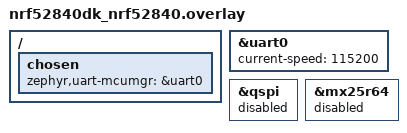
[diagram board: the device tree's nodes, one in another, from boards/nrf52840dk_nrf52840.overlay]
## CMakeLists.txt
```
cmake_minimum_required(VERSION 3.20.0)

find_package(Zephyr REQUIRED HINTS $ENV{ZEPHYR_BASE})
project(tx_node)

target_sources(app PRIVATE
	src/main.c
	src/ble_link.c
	src/packet_framer.c
	src/tsync.c
	src/dfu_auth.c
	src/wdt_monitor.c
	src/imu_uart_driver.c
	src/uwb_driver.c
)

target_include_directories(app PRIVATE
	${CMAKE_CURRENT_SOURCE_DIR}/include
	${CMAKE_CURRENT_SOURCE_DIR}/../shared/include
)
```

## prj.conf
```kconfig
CONFIG_BT=y
CONFIG_BT_PERIPHERAL=y
CONFIG_BT_CENTRAL=n
CONFIG_BT_DEVICE_NAME="BSGR_TX01"
CONFIG_BT_DEVICE_APPEARANCE=0
CONFIG_BT_SMP=y
CONFIG_BT_PRIVACY=y
CONFIG_BT_BONDABLE=y
CONFIG_BT_SETTINGS=y
CONFIG_BT_GATT_DYNAMIC_DB=y
CONFIG_BT_GATT_SERVICE_CHANGED=y
CONFIG_BT_MAX_CONN=1
CONFIG_BT_NUS=y
CONFIG_BT_NUS_CLIENT=n
CONFIG_BT_CTLR_PHY_2M=y
CONFIG_BT_USER_PHY_UPDATE=y
CONFIG_BT_CTLR_DATA_LENGTH_MAX=251
CONFIG_BT_L2CAP_TX_MTU=247
CONFIG_BT_BUF_ACL_RX_SIZE=251
CONFIG_BT_BUF_ACL_TX_SIZE=251
CONFIG_BT_BUF_ACL_RX_COUNT=8
CONFIG_BT_BUF_ACL_TX_COUNT=12
CONFIG_BT_L2CAP_TX_BUF_COUNT=12
CONFIG_BT_BUF_CMD_TX_COUNT=6
CONFIG_BT_BUF_EVT_RX_SIZE=255
CONFIG_BT_BUF_EVT_RX_COUNT=8

CONFIG_BOOTLOADER_MCUBOOT=y
CONFIG_MCUBOOT_BOOTUTIL_LIB=y
CONFIG_MCUBOOT_IMGTOOL_SIGN_VERSION="0.1.0+4"
CONFIG_FLASH=y
CONFIG_FLASH_PAGE_LAYOUT=y
CONFIG_FLASH_MAP=y
CONFIG_STREAM_FLASH=y
CONFIG_IMG_MANAGER=y
CONFIG_MCUMGR=y
CONFIG_MCUMGR_GRP_IMG=y
CONFIG_MCUMGR_GRP_OS=y
CONFIG_MCUMGR_GRP_OS_BOOTLOADER_INFO=y
CONFIG_MCUMGR_GRP_OS_MCUMGR_PARAMS=y
CONFIG_MCUMGR_TRANSPORT_BT=y
CONFIG_MCUMGR_TRANSPORT_BT_PERM_RW_AUTHEN=y
CONFIG_MCUMGR_TRANSPORT_BT_CONN_PARAM_CONTROL=y
CONFIG_MCUMGR_TRANSPORT_BT_REASSEMBLY=y
CONFIG_MCUMGR_TRANSPORT_NETBUF_SIZE=768
CONFIG_ZCBOR=y
CONFIG_CRC=y
CONFIG_NET_BUF=y

CONFIG_SETTINGS=y
CONFIG_REBOOT=y
CONFIG_WATCHDOG=y
CONFIG_GPIO=y
CONFIG_SERIAL=y
CONFIG_UART_INTERRUPT_DRIVEN=y
CONFIG_RING_BUFFER=y
CONFIG_ASSERT=y

CONFIG_LOG=y
CONFIG_LOG_DEFAULT_LEVEL=3
CONFIG_LOG_MODE_DEFERRED=y
CONFIG_LOG_BACKEND_RTT=y
CONFIG_LOG_BACKEND_UART=n
CONFIG_USE_SEGGER_RTT=y
CONFIG_RTT_CONSOLE=y
CONFIG_CONSOLE=y
CONFIG_UART_CONSOLE=n
CONFIG_PRINTK=y

CONFIG_MAIN_STACK_SIZE=4096
CONFIG_SYSTEM_WORKQUEUE_STACK_SIZE=4096
CONFIG_ISR_STACK_SIZE=2048
CONFIG_HEAP_MEM_POOL_SIZE=8192
```

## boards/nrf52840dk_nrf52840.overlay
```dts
/ {
	chosen {
		zephyr,uart-mcumgr = &uart0;
	};
};

&uart0 {
	status = "okay";
	current-speed = <115200>;
};

&qspi {
	status = "disabled";
};

&mx25r64 {
	status = "disabled";
};
```

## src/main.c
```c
#include <zephyr/kernel.h>
#include <zephyr/logging/log.h>

#include "ble_link.h"
#include "dfu_auth.h"
#include "imu_uart_driver.h"
#include "packet_framer.h"
#include "tsync.h"
#include "tx_node.h"
#include "uwb_driver.h"
#include "wdt_monitor.h"

LOG_MODULE_REGISTER(tx_main, LOG_LEVEL_INF);

static struct k_work_delayable tx_service_work;
static uint16_t tx_seq;
static int64_t last_status_ms;

static void tx_submit_boot_status(enum bsgr_status_code code, uint16_t detail, uint32_t value)
{
	struct bsgr_status_payload status = {
		.status_code = code,
		.origin = BSGR_ORIGIN_SYSTEM,
		.detail = detail,
		.value = value,
	};
	struct bsgr_tx_frame frame;

	if (packet_framer_build_status(BSGR_TX_DEVICE_ID, tx_seq++, &status, &frame) == 0) {
		(void)ble_link_submit_frame(&frame);
	}
}

static void tx_drain_imu_samples(void)
{
	struct bsgr_imu_sample *sample;

	while ((sample = imu_uart_driver_pop_sample()) != NULL) {
		struct bsgr_imu_batch_meta meta = {
			.stream_flags = BSGR_STREAM_FLAG_IMU,
			.sample_count = 1U,
			.parser_flags = sample->parser_flags,
			.reserved = 0U,
			.host_capture_ticks = sample->host_capture_ticks,
			.sample_stride = sample->raw_len,
			.raw_bytes = sample->raw_len,
		};
		struct bsgr_tx_frame frame;

		if (packet_framer_build_imu(BSGR_TX_DEVICE_ID, tx_seq++, &meta,
					    sample->raw, sample->raw_len, &frame) == 0) {
			(void)ble_link_submit_frame(&frame);
		}
		k_free(sample);
	}
}

static void tx_drain_uwb_records(void)
{
	struct bsgr_uwb_record *record;

	while ((record = uwb_driver_pop_record()) != NULL) {
		struct bsgr_uwb_report_meta meta = {
			.stream_flags = BSGR_STREAM_FLAG_UWB,
			.record_count = 1U,
			.parser_flags = record->parser_flags,
			.reserved = 0U,
			.host_capture_ticks = record->host_capture_ticks,
			.record_stride = record->raw_len,
			.raw_bytes = record->raw_len,
		};
		struct bsgr_tx_frame frame;

		if (packet_framer_build_uwb(BSGR_TX_DEVICE_ID, tx_seq++, &meta,
					    record->raw, record->raw_len, &frame) == 0) {
			(void)ble_link_submit_frame(&frame);
		}
		k_free(record);
	}
}

static void tx_service_work_handler(struct k_work *work)
{
	int64_t now_ms = k_uptime_get();

	ARG_UNUSED(work);

	imu_uart_driver_process();
	uwb_driver_process();
	tx_drain_imu_samples();
	tx_drain_uwb_records();
	ble_link_schedule_drain();
	wdt_monitor_feed();

	if ((now_ms - last_status_ms) >= BSGR_TX_STATUS_PERIOD_MS) {
		tx_submit_boot_status(BSGR_STATUS_STREAM_IDLE, 0U,
				     (uint32_t)ble_link_is_connected());
		last_status_ms = now_ms;
	}

	(void)k_work_reschedule(&tx_service_work, K_MSEC(BSGR_TX_SERVICE_PERIOD_MS));
}

int tx_main_init(void)
{
	int err;

	LOG_INF("BSGR TX framework bring-up");

	dfu_auth_init();
	tsync_init();

	err = wdt_monitor_init();
	if (err != 0) {
		return err;
	}

	err = imu_uart_driver_init();
	if (err != 0) {
		LOG_WRN("IMU driver init degraded: %d", err);
	}

	err = uwb_driver_init();
	if (err != 0) {
		LOG_WRN("UWB driver init degraded: %d", err);
	}

	(void)imu_uart_driver_start();
	(void)uwb_driver_start();

	err = ble_link_init(BSGR_TX_DEVICE_ID);
	if (err != 0) {
		return err;
	}

	k_work_init_delayable(&tx_service_work, tx_service_work_handler);
	tx_seq = 0U;
	last_status_ms = 0;
	tx_submit_boot_status(BSGR_STATUS_BOOT, 0U, tsync_get_session_id());
	(void)k_work_reschedule(&tx_service_work, K_NO_WAIT);

	return 0;
}

int main(void)
{
	int err = tx_main_init();

	if (err != 0) {
		LOG_ERR("tx_main_init failed: %d", err);
		return err;
	}

	while (1) {
		k_sleep(K_SECONDS(1));
	}

	return 0;
}
```

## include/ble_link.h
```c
#ifndef BSGR_TX_BLE_LINK_H_
#define BSGR_TX_BLE_LINK_H_

#include <stdbool.h>
#include <stddef.h>
#include <stdint.h>

#include "packet_framer.h"

int ble_link_init(uint16_t device_id);
int ble_link_submit_frame(const struct bsgr_tx_frame *frame);
void ble_link_schedule_drain(void);
bool ble_link_is_connected(void);

#endif /* BSGR_TX_BLE_LINK_H_ */
```

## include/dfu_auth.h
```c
#ifndef BSGR_TX_DFU_AUTH_H_
#define BSGR_TX_DFU_AUTH_H_

#include <stdbool.h>
#include <stdint.h>

#include "bsgr_protocol.h"

struct bsgr_dfu_auth_state {
	bool prepared;
	bool authorized;
	bool active;
	uint16_t session_id;
	uint16_t last_request_id;
	enum bsgr_cmd_result last_result;
};

void dfu_auth_init(void);
void dfu_auth_prepare(uint16_t request_id);
void dfu_auth_set_authorized(bool authorized, uint16_t request_id);
void dfu_auth_begin(uint16_t session_id);
void dfu_auth_end(void);
bool dfu_auth_is_permitted(void);
const struct bsgr_dfu_auth_state *dfu_auth_state_get(void);

#endif /* BSGR_TX_DFU_AUTH_H_ */
```

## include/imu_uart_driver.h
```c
#ifndef BSGR_TX_IMU_UART_DRIVER_H_
#define BSGR_TX_IMU_UART_DRIVER_H_

#include <stdbool.h>
#include <stddef.h>
#include <stdint.h>

#include "bsgr_protocol.h"

struct bsgr_imu_sample {
	void *fifo_reserved;
	uint32_t host_capture_ticks;
	uint16_t parser_flags;
	uint16_t raw_len;
	uint8_t raw[BSGR_IMU_MAX_RAW_FRAME_LEN];
};

int imu_uart_driver_init(void);
int imu_uart_driver_start(void);
void imu_uart_driver_stop(void);
bool imu_uart_driver_is_bound(void);
void imu_uart_driver_process(void);
int imu_uart_driver_ingest_bytes(const uint8_t *data, size_t len, uint32_t capture_ticks);
struct bsgr_imu_sample *imu_uart_driver_pop_sample(void);

#endif /* BSGR_TX_IMU_UART_DRIVER_H_ */
```

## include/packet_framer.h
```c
#ifndef BSGR_TX_PACKET_FRAMER_H_
#define BSGR_TX_PACKET_FRAMER_H_

#include <stddef.h>
#include <stdint.h>

#include "bsgr_protocol.h"

struct bsgr_tx_frame {
	size_t len;
	uint8_t data[BSGR_MAX_FRAME_LEN];
};

struct bsgr_imu_sample;
struct bsgr_uwb_record;

int packet_framer_build_status(uint16_t device_id,
			       uint16_t seq,
			       const struct bsgr_status_payload *payload,
			       struct bsgr_tx_frame *frame);
int packet_framer_build_cmd_ack(uint16_t device_id,
				uint16_t seq,
				const struct bsgr_cmd_ack_payload *payload,
				struct bsgr_tx_frame *frame);
int packet_framer_build_tsync(uint16_t device_id,
			      uint16_t seq,
			      const struct bsgr_tsync_payload *payload,
			      struct bsgr_tx_frame *frame);
int packet_framer_build_imu(uint16_t device_id,
			    uint16_t seq,
			    const struct bsgr_imu_batch_meta *meta,
			    const uint8_t *raw_payload,
			    size_t raw_len,
			    struct bsgr_tx_frame *frame);
int packet_framer_build_uwb(uint16_t device_id,
			    uint16_t seq,
			    const struct bsgr_uwb_report_meta *meta,
			    const uint8_t *raw_payload,
			    size_t raw_len,
			    struct bsgr_tx_frame *frame);

#endif /* BSGR_TX_PACKET_FRAMER_H_ */
```

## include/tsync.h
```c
#ifndef BSGR_TX_TSYNC_H_
#define BSGR_TX_TSYNC_H_

#include <stdint.h>

#include "bsgr_protocol.h"

struct bsgr_tsync_state {
	int32_t host_offset_ms;
	uint16_t session_id;
	uint16_t last_request_id;
};

void tsync_init(void);
void tsync_set_host_offset_ms(int32_t offset_ms);
int32_t tsync_get_host_offset_ms(void);
uint16_t tsync_next_request_id(void);
uint16_t tsync_get_session_id(void);
void tsync_advance_session(void);
void tsync_fill_payload(struct bsgr_tsync_payload *payload, uint8_t role, uint32_t reference_ticks);

#endif /* BSGR_TX_TSYNC_H_ */
```

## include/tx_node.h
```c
#ifndef BSGR_TX_NODE_H_
#define BSGR_TX_NODE_H_

#include <stdint.h>

#define BSGR_TX_DEVICE_ID 0x1001u
#define BSGR_TX_SERVICE_PERIOD_MS 25u
#define BSGR_TX_STATUS_PERIOD_MS 1000u

int tx_main_init(void);

#endif /* BSGR_TX_NODE_H_ */
```

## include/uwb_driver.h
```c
#ifndef BSGR_TX_UWB_DRIVER_H_
#define BSGR_TX_UWB_DRIVER_H_

#include <stdbool.h>
#include <stddef.h>
#include <stdint.h>

#include "bsgr_protocol.h"

struct bsgr_uwb_record {
	void *fifo_reserved;
	uint32_t host_capture_ticks;
	uint16_t parser_flags;
	uint16_t raw_len;
	uint8_t raw[BSGR_UWB_MAX_RAW_RECORD_LEN];
};

int uwb_driver_init(void);
int uwb_driver_start(void);
void uwb_driver_stop(void);
bool uwb_driver_is_bound(void);
void uwb_driver_process(void);
int uwb_driver_ingest_record(const uint8_t *data, size_t len, uint32_t capture_ticks);
struct bsgr_uwb_record *uwb_driver_pop_record(void);

#endif /* BSGR_TX_UWB_DRIVER_H_ */
```

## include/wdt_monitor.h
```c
#ifndef BSGR_TX_WDT_MONITOR_H_
#define BSGR_TX_WDT_MONITOR_H_

int wdt_monitor_init(void);
void wdt_monitor_feed(void);

#endif /* BSGR_TX_WDT_MONITOR_H_ */
```

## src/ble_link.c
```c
#include <errno.h>
#include <string.h>

#include <zephyr/bluetooth/bluetooth.h>
#include <zephyr/bluetooth/conn.h>
#include <zephyr/bluetooth/gatt.h>
#include <zephyr/bluetooth/hci.h>
#include <zephyr/kernel.h>
#include <zephyr/logging/log.h>
#include <zephyr/settings/settings.h>
#include <zephyr/sys/util.h>

#include <bluetooth/services/nus.h>

#include "ble_link.h"

LOG_MODULE_REGISTER(tx_ble_link, LOG_LEVEL_INF);

#define BSGR_TX_FRAME_QUEUE_DEPTH 12

static struct bt_conn *current_conn;
static struct k_msgq tx_frame_msgq;
static struct bsgr_tx_frame tx_frame_buffer[BSGR_TX_FRAME_QUEUE_DEPTH];
static struct k_work tx_drain_work;

static const struct bt_data ad[] = {
	BT_DATA_BYTES(BT_DATA_FLAGS, (BT_LE_AD_GENERAL | BT_LE_AD_NO_BREDR)),
};

static const struct bt_data sd[] = {
	BT_DATA(BT_DATA_NAME_COMPLETE, CONFIG_BT_DEVICE_NAME, sizeof(CONFIG_BT_DEVICE_NAME) - 1),
};

static int start_advertising(void)
{
	int err;

	err = bt_le_adv_start(BT_LE_ADV_CONN, ad, ARRAY_SIZE(ad), sd, ARRAY_SIZE(sd));
	if ((err == -EALREADY) || (err == -EAGAIN)) {
		return 0;
	}

	return err;
}

static void tx_drain_work_handler(struct k_work *work)
{
	struct bsgr_tx_frame frame;
	int err;

	ARG_UNUSED(work);

	if (current_conn == NULL) {
		return;
	}

	while (k_msgq_get(&tx_frame_msgq, &frame, K_NO_WAIT) == 0) {
		err = bt_nus_send(current_conn, frame.data, frame.len);
		if (err != 0) {
			LOG_WRN("bt_nus_send failed: %d", err);
			break;
		}
	}
}

static void connected(struct bt_conn *conn, uint8_t err)
{
	if (err != 0U) {
		LOG_WRN("Connection failed: 0x%02x", err);
		return;
	}

	if (current_conn != NULL) {
		bt_conn_unref(current_conn);
	}

	current_conn = bt_conn_ref(conn);
	LOG_INF("BLE connected");
	k_work_submit(&tx_drain_work);
}

static void disconnected(struct bt_conn *conn, uint8_t reason)
{
	int err;

	ARG_UNUSED(conn);

	if (current_conn != NULL) {
		bt_conn_unref(current_conn);
		current_conn = NULL;
	}

	LOG_INF("BLE disconnected: 0x%02x", reason);

	err = start_advertising();
	if (err != 0) {
		LOG_ERR("Failed to restart advertising: %d", err);
	}
}

BT_CONN_CB_DEFINE(tx_conn_callbacks) = {
	.connected = connected,
	.disconnected = disconnected,
};

static void nus_rx_cb(struct bt_conn *conn, const uint8_t *const data, uint16_t len)
{
	ARG_UNUSED(conn);

	LOG_INF("NUS RX control stub: %u bytes", len);
	if (len >= sizeof(struct bsgr_frame_header)) {
		const struct bsgr_frame_header *hdr = (const struct bsgr_frame_header *)data;

		if (bsgr_frame_header_is_valid(hdr)) {
			LOG_INF("Received frame type 0x%02x seq %u", hdr->frame_type, hdr->seq);
		}
	}
}

static struct bt_nus_cb nus_callbacks = {
	.received = nus_rx_cb,
};

int ble_link_init(uint16_t device_id)
{
	int err;

	ARG_UNUSED(device_id);

	k_msgq_init(&tx_frame_msgq, (char *)tx_frame_buffer,
		    sizeof(struct bsgr_tx_frame), ARRAY_SIZE(tx_frame_buffer));
	k_work_init(&tx_drain_work, tx_drain_work_handler);

	err = bt_enable(NULL);
	if (err != 0) {
		return err;
	}

	if (IS_ENABLED(CONFIG_SETTINGS)) {
		settings_load();
	}

	err = bt_nus_init(&nus_callbacks);
	if (err != 0) {
		return err;
	}

	err = start_advertising();
	if (err != 0) {
		return err;
	}

	LOG_INF("BSGR TX advertising with NUS and separate SMP GATT service");
	return 0;
}

int ble_link_submit_frame(const struct bsgr_tx_frame *frame)
{
	int err;

	if (frame == NULL) {
		return -EINVAL;
	}

	err = k_msgq_put(&tx_frame_msgq, frame, K_NO_WAIT);
	if (err == 0) {
		k_work_submit(&tx_drain_work);
	}

	return err;
}

void ble_link_schedule_drain(void)
{
	k_work_submit(&tx_drain_work);
}

bool ble_link_is_connected(void)
{
	return current_conn != NULL;
}
```

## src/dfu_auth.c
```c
#include "dfu_auth.h"

static struct bsgr_dfu_auth_state g_dfu_auth_state;

void dfu_auth_init(void)
{
	g_dfu_auth_state.prepared = false;
	g_dfu_auth_state.authorized = false;
	g_dfu_auth_state.active = false;
	g_dfu_auth_state.session_id = 0U;
	g_dfu_auth_state.last_request_id = 0U;
	g_dfu_auth_state.last_result = BSGR_CMD_RESULT_DEFERRED;
}

void dfu_auth_prepare(uint16_t request_id)
{
	g_dfu_auth_state.prepared = true;
	g_dfu_auth_state.last_request_id = request_id;
	g_dfu_auth_state.last_result = BSGR_CMD_RESULT_DEFERRED;
}

void dfu_auth_set_authorized(bool authorized, uint16_t request_id)
{
	g_dfu_auth_state.authorized = authorized;
	g_dfu_auth_state.last_request_id = request_id;
	g_dfu_auth_state.last_result = authorized ? BSGR_CMD_RESULT_OK : BSGR_CMD_RESULT_REJECTED;
}

void dfu_auth_begin(uint16_t session_id)
{
	g_dfu_auth_state.active = g_dfu_auth_state.authorized;
	g_dfu_auth_state.session_id = session_id;
}

void dfu_auth_end(void)
{
	g_dfu_auth_state.active = false;
	g_dfu_auth_state.prepared = false;
}

bool dfu_auth_is_permitted(void)
{
	return g_dfu_auth_state.prepared && g_dfu_auth_state.authorized;
}

const struct bsgr_dfu_auth_state *dfu_auth_state_get(void)
{
	return &g_dfu_auth_state;
}
```

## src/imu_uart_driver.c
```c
#include <errno.h>
#include <string.h>

#include <zephyr/kernel.h>
#include <zephyr/logging/log.h>
#include <zephyr/sys/ring_buffer.h>

#include "imu_uart_driver.h"

LOG_MODULE_REGISTER(tx_imu_uart, LOG_LEVEL_INF);

#define BSGR_IMU_RX_RING_SIZE 256
#define BSGR_IMU_FRAME_BYTES 11
#define BSGR_IMU_SAMPLE_POOL_COUNT 8

RING_BUF_DECLARE(imu_rx_ring, BSGR_IMU_RX_RING_SIZE);
K_FIFO_DEFINE(imu_sample_fifo);
K_HEAP_DEFINE(imu_heap, BSGR_IMU_SAMPLE_POOL_COUNT * sizeof(struct bsgr_imu_sample));

static bool imu_bound;
static bool imu_started;

int imu_uart_driver_init(void)
{
	ring_buf_reset(&imu_rx_ring);
	imu_bound = false;
	imu_started = false;
	LOG_INF("IMU UART driver initialized in conservative parser mode");
	return 0;
}

int imu_uart_driver_start(void)
{
	imu_started = true;
	return imu_bound ? 0 : -ENODEV;
}

void imu_uart_driver_stop(void)
{
	imu_started = false;
}

bool imu_uart_driver_is_bound(void)
{
	return imu_bound;
}

int imu_uart_driver_ingest_bytes(const uint8_t *data, size_t len, uint32_t capture_ticks)
{
	struct bsgr_imu_sample *sample;

	if ((data == NULL) || (len == 0U)) {
		return -EINVAL;
	}

	if (len < BSGR_IMU_FRAME_BYTES) {
		return ring_buf_put(&imu_rx_ring, data, len) == len ? 0 : -ENOSPC;
	}

	sample = k_heap_alloc(&imu_heap, sizeof(*sample), K_NO_WAIT);
	if (sample == NULL) {
		return -ENOMEM;
	}

	memset(sample, 0, sizeof(*sample));
	sample->host_capture_ticks = capture_ticks;
	sample->raw_len = MIN(len, (size_t)BSGR_IMU_MAX_RAW_FRAME_LEN);
	memcpy(sample->raw, data, sample->raw_len);
	sample->parser_flags = BSGR_PARSER_FLAG_STUB_DECODE;

	if ((sample->raw_len >= BSGR_IMU_FRAME_BYTES) && (sample->raw[0] == 0x55U)) {
		sample->parser_flags |= BSGR_PARSER_FLAG_CANDIDATE_FRAME;
	}

	k_fifo_put(&imu_sample_fifo, sample);
	return 0;
}

void imu_uart_driver_process(void)
{
	uint8_t candidate[BSGR_IMU_FRAME_BYTES];
	uint32_t got;

	if (!imu_started) {
		return;
	}

	while (ring_buf_size_get(&imu_rx_ring) >= BSGR_IMU_FRAME_BYTES) {
		got = ring_buf_get(&imu_rx_ring, candidate, sizeof(candidate));
		if (got != sizeof(candidate)) {
			break;
		}

		(void)imu_uart_driver_ingest_bytes(candidate, sizeof(candidate), k_uptime_ticks());
	}
}

struct bsgr_imu_sample *imu_uart_driver_pop_sample(void)
{
	return k_fifo_get(&imu_sample_fifo, K_NO_WAIT);
}
```

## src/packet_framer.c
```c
#include <errno.h>
#include <string.h>

#include "imu_uart_driver.h"
#include "packet_framer.h"
#include "uwb_driver.h"

static int packet_framer_build(uint16_t device_id,
			       uint16_t seq,
			       uint8_t frame_type,
			       uint8_t flags,
			       const void *meta,
			       size_t meta_len,
			       const uint8_t *raw_payload,
			       size_t raw_len,
			       struct bsgr_tx_frame *frame)
{
	struct bsgr_frame_header *hdr;
	size_t payload_len;

	if ((frame == NULL) || (meta == NULL)) {
		return -EINVAL;
	}

	payload_len = meta_len + raw_len;
	if (payload_len > BSGR_MAX_FRAME_PAYLOAD_LEN) {
		return -EMSGSIZE;
	}

	hdr = (struct bsgr_frame_header *)frame->data;
	bsgr_frame_header_init(hdr, frame_type, flags, (uint8_t)payload_len, device_id, seq);

	memcpy(frame->data + sizeof(*hdr), meta, meta_len);
	if ((raw_payload != NULL) && (raw_len > 0U)) {
		memcpy(frame->data + sizeof(*hdr) + meta_len, raw_payload, raw_len);
	}

	frame->len = sizeof(*hdr) + payload_len;
	return 0;
}

int packet_framer_build_status(uint16_t device_id,
			       uint16_t seq,
			       const struct bsgr_status_payload *payload,
			       struct bsgr_tx_frame *frame)
{
	return packet_framer_build(device_id, seq, BSGR_FRAME_TYPE_STATUS, 0U,
				   payload, sizeof(*payload), NULL, 0U, frame);
}

int packet_framer_build_cmd_ack(uint16_t device_id,
				uint16_t seq,
				const struct bsgr_cmd_ack_payload *payload,
				struct bsgr_tx_frame *frame)
{
	return packet_framer_build(device_id, seq, BSGR_FRAME_TYPE_CMD_ACK,
				   BSGR_FRAME_FLAG_ACK_REQUIRED, payload, sizeof(*payload),
				   NULL, 0U, frame);
}

int packet_framer_build_tsync(uint16_t device_id,
			      uint16_t seq,
			      const struct bsgr_tsync_payload *payload,
			      struct bsgr_tx_frame *frame)
{
	return packet_framer_build(device_id, seq, BSGR_FRAME_TYPE_TSYNC,
				   BSGR_FRAME_FLAG_HOST_TIMED, payload, sizeof(*payload),
				   NULL, 0U, frame);
}

int packet_framer_build_imu(uint16_t device_id,
			    uint16_t seq,
			    const struct bsgr_imu_batch_meta *meta,
			    const uint8_t *raw_payload,
			    size_t raw_len,
			    struct bsgr_tx_frame *frame)
{
	return packet_framer_build(device_id, seq, BSGR_FRAME_TYPE_IMU_BATCH,
				   BSGR_FRAME_FLAG_HOST_TIMED, meta, sizeof(*meta),
				   raw_payload, raw_len, frame);
}

int packet_framer_build_uwb(uint16_t device_id,
			    uint16_t seq,
			    const struct bsgr_uwb_report_meta *meta,
			    const uint8_t *raw_payload,
			    size_t raw_len,
			    struct bsgr_tx_frame *frame)
{
	return packet_framer_build(device_id, seq, BSGR_FRAME_TYPE_UWB_REPORT,
				   BSGR_FRAME_FLAG_HOST_TIMED | BSGR_FRAME_FLAG_STUB_DATA,
				   meta, sizeof(*meta), raw_payload, raw_len, frame);
}
```
